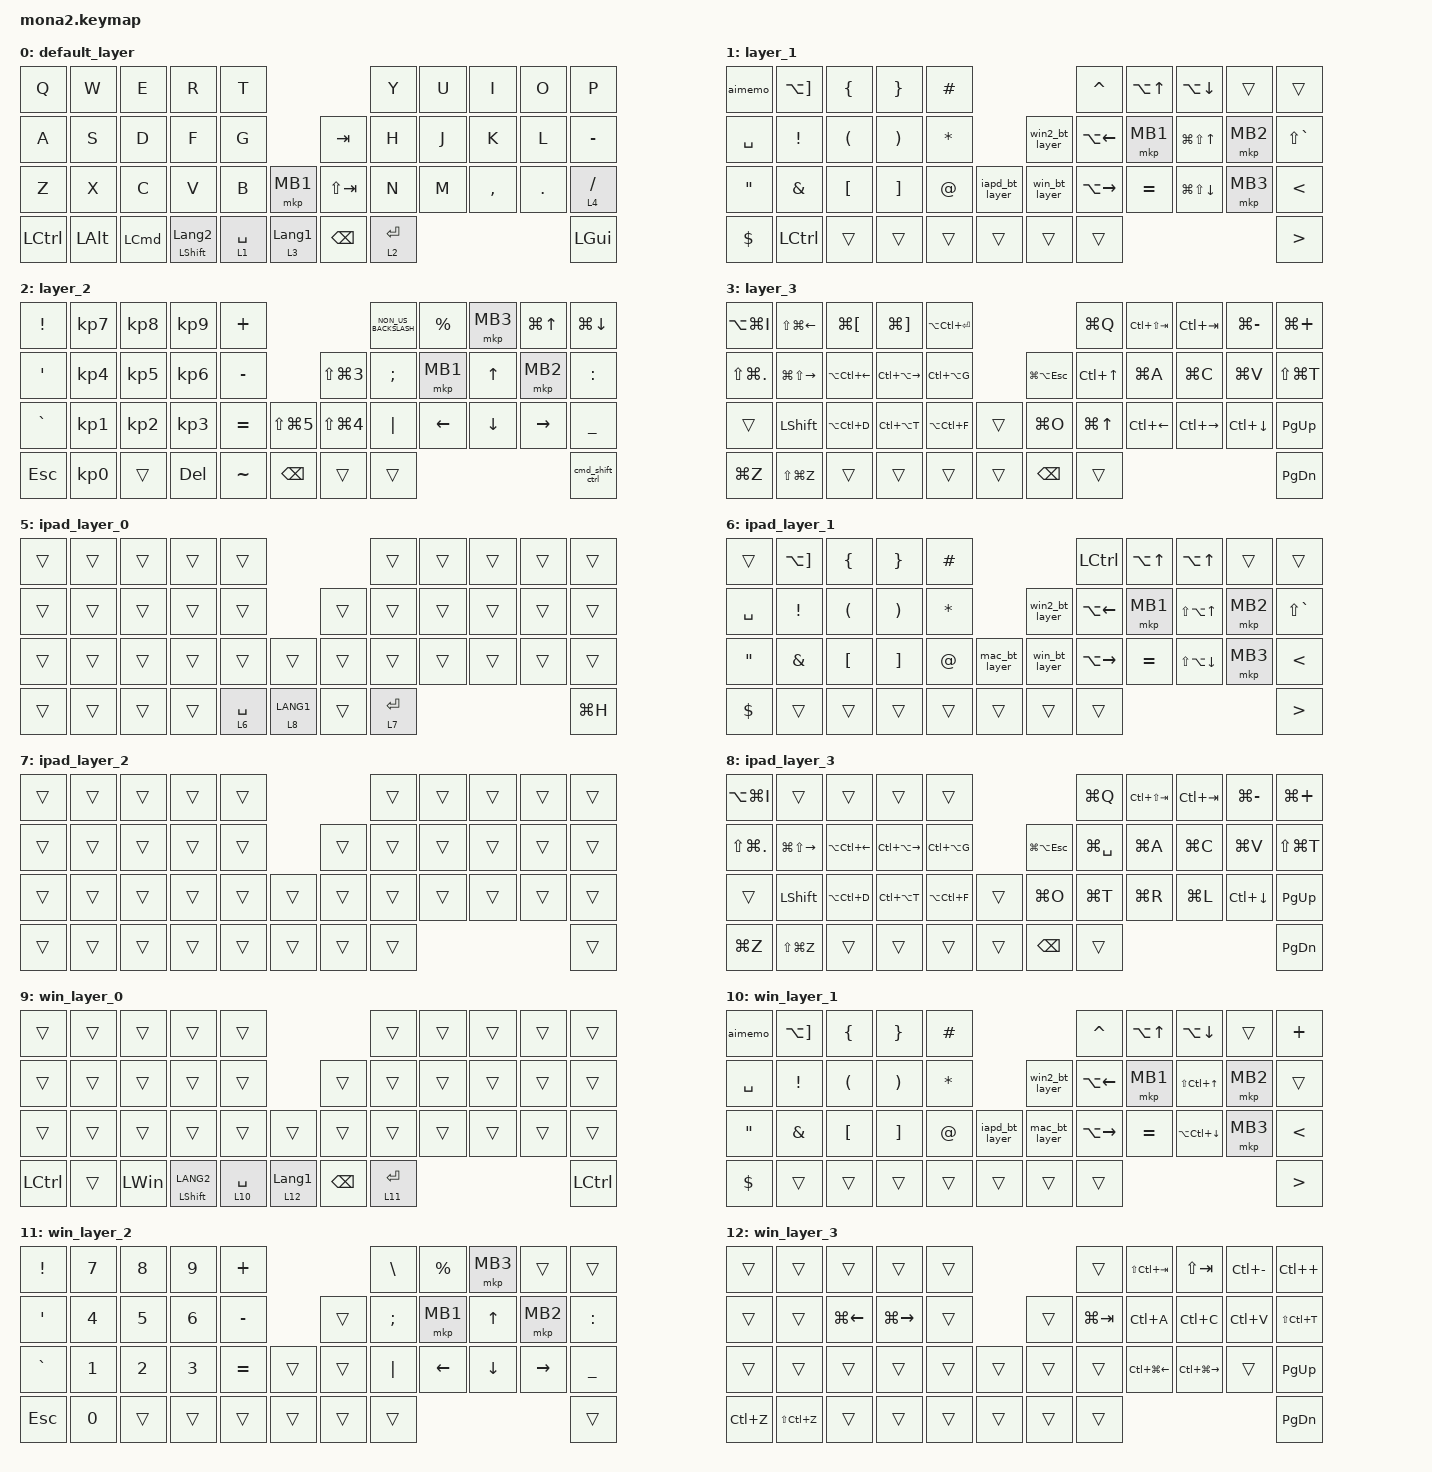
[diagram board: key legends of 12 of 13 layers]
#include <input/processors.dtsi>
#include <dt-bindings/zmk/input_transform.h>
#include <zephyr/dt-bindings/input/input-event-codes.h>
#include <behaviors.dtsi>
#include <dt-bindings/zmk/bt.h>
#include <dt-bindings/zmk/keys.h>
#include <dt-bindings/zmk/pointing.h>

#define ZMK_POINTING_DEFAULT_SCRL_VAL 100
#define MOUSE 5
#define SCROLL 6

&mt {
    flavor = "balanced";
    quick-tap-ms = <0>;
};

&lt {
    quick-tap-ms = <300>;
    flavor = "balanced";
};

/ {
    combos {
        compatible = "zmk,combos";

        layer4_ESC {
            bindings = <&lt 4 ESC>;
            key-positions = <39 38>;
        };

        tab {
            bindings = <&kp TAB>;
            key-positions = <11 12>;
        };

        cmd {
            bindings = <&none>;
            key-positions = <29 23 12>;
        };

        plus {
            bindings = <&none>;
            key-positions = <37 9>;
        };

        shift {
            bindings = <&none>;
            key-positions = <11 16 7 13 4>;
        };

        ctrl {
            bindings = <&none>;
            key-positions = <23 4 3 19>;
        };
    };

    macros {
        to_layer_0: to_layer_0 {
            compatible = "zmk,behavior-macro-one-param";
            #binding-cells = <1>;
            bindings = <&to 0 &macro_param_1to1 &kp MACRO_PLACEHOLDER>;
            label = "TO_LAYER_0";
        };

        mac_bt_layer: mac_bt_layer {
            compatible = "zmk,behavior-macro";
            #binding-cells = <0>;
            bindings = <&bt BT_SEL 0>, <&macro_wait_time 200>, <&to 0>;

            label = "MAC_BT_LAYER";
        };

        iapd_bt_layer: iapd_bt_layer {
            compatible = "zmk,behavior-macro";
            #binding-cells = <0>;
            bindings = <&bt BT_SEL 1>, <&macro_wait_time 200>, <&to 5>;

            label = "IAPD_BT_LAYER";
        };

        win_bt_layer: win_bt_layer {
            compatible = "zmk,behavior-macro";
            #binding-cells = <0>;
            bindings = <&bt BT_SEL 2>, <&macro_wait_time 200>, <&to 9>;

            label = "WIN_BT_LAYER";
        };

        win2_bt_layer: win2_bt_layer {
            compatible = "zmk,behavior-macro";
            #binding-cells = <0>;
            bindings = <&bt BT_SEL 3>, <&macro_wait_time 200>, <&to 9>;

            label = "WIN2_BT_LAYER";
        };

        aimemo: aimemo {
            compatible = "zmk,behavior-macro";
            #binding-cells = <0>;
            bindings =
                <&macro_press>,
                <&kp LEFT_SHIFT &kp LEFT_ALT &kp D>,
                <&macro_release>,
                <&kp LEFT_SHIFT &kp LEFT_ALT &kp D>;

            label = "AIMEMO";
        };

        cmd_shift_ctrl: cmd_shift_ctrl {
            compatible = "zmk,behavior-macro";
            #binding-cells = <0>;
            bindings = <&kp C &kp M &kp D &kp UNDERSCORE &kp S &kp H &kp I &kp F &kp T &kp UNDERSCORE &kp A &kp L &kp T &kp UNDERSCORE>;
            label = "CMD_SHIFT_CTRL";
        };

        cmd_shift_ctrl__: cmd_shift_ctrl__ {
            compatible = "zmk,behavior-macro";
            #binding-cells = <0>;
            bindings = <&kp LEFT_GUI &kp LEFT_SHIFT &kp LEFT_CONTROL>;
            label = "CMD_SHIFT_CTRL__";
        };

        loupedeck_open: loupedeck {
            compatible = "zmk,behavior-macro";
            #binding-cells = <0>;
            bindings = <&kp LS(LG(LA(L)))>;
            label = "LOUPEDECK";
        };

        Googlechroom_open: Googlechroom_open {
            compatible = "zmk,behavior-macro";
            #binding-cells = <0>;
            bindings = <&kp LS(LA(LG(C)))>, <&macro_press>;

            label = "GOOGLECHROOM_OPEN";
        };

        obsidian_open: obsidian_open {
            compatible = "zmk,behavior-macro";
            #binding-cells = <0>;
            bindings = <&kp LS(LA(LG(O)))>;
            label = "OBSIDIAN_OPEN";
        };

        cco_foruda_open: cco_foruda_open {
            compatible = "zmk,behavior-macro";
            #binding-cells = <0>;
            bindings = <&kp LS(LA(LG(H)))>;
            label = "CCO_FORUDA_OPEN";
        };

        new_d_folder: new_d_folder {
            compatible = "zmk,behavior-macro";
            #binding-cells = <0>;
            bindings = <&kp LS(LA(LG(Y)))>;
            label = "NEW_D_FOLDER";
        };

        zmk_git_url_open: zmk_git_url_open {
            compatible = "zmk,behavior-macro";
            #binding-cells = <0>;
            bindings = <&kp LS(LA(LG(A)))>;
            label = "ZMK_GIT_URL_OPEN";
        };

        System_keyboard_shortcut: System_keyboard_shortcut {
            compatible = "zmk,behavior-macro";
            #binding-cells = <0>;
            bindings = <&kp LS(LA(LG(B)))>;
            label = "SYSTEM_KEYBOARD_SHORTCUT";
        };

        System_Bluetooth_open: System_Bluetooth_open {
            compatible = "zmk,behavior-macro";
            #binding-cells = <0>;
            bindings = <&kp LS(LA(LG(E)))>;
            label = "SYSTEM_BLUETOOTH_OPEN";
        };

        vscode_open: vscode_open {
            compatible = "zmk,behavior-macro";
            #binding-cells = <0>;
            bindings = <&kp LS(LA(LG(F)))>;
            label = "VSCODE_OPEN";
        };

        slack_open: slack_open {
            compatible = "zmk,behavior-macro";
            #binding-cells = <0>;
            bindings = <&kp LS(LA(LG(G)))>;
            label = "SLACK_OPEN";
        };
    };

    behaviors {
        lt_to_layer_0: lt_to_layer_0 {
            compatible = "zmk,behavior-hold-tap";
            label = "LAYER_TAP_TO_0";
            bindings = <&mo>, <&to_layer_0>;

            #binding-cells = <2>;
            tapping-term-ms = <200>;
        };

        scroll_up_down: mouse_wheel_up_down {
            compatible = "zmk,behavior-sensor-rotate";
            #sensor-binding-cells = <0>;
            bindings = <&msc SCRL_DOWN>, <&msc SCRL_UP>;

            tap-ms = <20>;
        };

        scroll_right_left: mouse_wheel_right_left {
            compatible = "zmk,behavior-sensor-rotate";
            #sensor-binding-cells = <0>;
            bindings = <&msc SCRL_LEFT>, <&msc SCRL_RIGHT>;

            tap-ms = <20>;
        };
    };

    keymap {
        compatible = "zmk,keymap";

        default_layer {
            bindings = <
&kp Q      &kp W         &kp E             &kp R                      &kp T                                           &kp Y        &kp U  &kp I      &kp O    &kp P
&kp A      &kp S         &kp D             &kp F                      &kp G                            &kp TAB        &kp H        &kp J  &kp K      &kp L    &kp MINUS
&kp Z      &kp X         &kp C             &kp V                      &kp B        &mkp MB1            &kp LS(TAB)    &kp N        &kp M  &kp COMMA  &kp DOT  &lt 4 SLASH
&kp LCTRL  &kp LEFT_ALT  &kp LEFT_COMMAND  &mt LEFT_SHIFT LANGUAGE_2  &lt 1 SPACE  &lt 3 LANGUAGE_1    &kp BACKSPACE  &lt 2 ENTER                             &kp LEFT_GUI
            >;

            sensor-bindings = <&scroll_up_down>;
        };

        layer_1 {
            bindings = <
&aimemo            &kp LA(RIGHT_BRACKET)  &kp LEFT_BRACE        &kp RIGHT_BRACE        &kp HASH                                        &kp CARET           &kp LA(UP_ARROW)  &kp LA(DOWN)          &trans    &trans
&kp SPACE          &kp EXCLAMATION        &kp LEFT_PARENTHESIS  &kp RIGHT_PARENTHESIS  &kp ASTERISK                    &win2_bt_layer  &kp LA(LEFT_ARROW)  &mkp MB1          &kp LG(LS(UP_ARROW))  &mkp MB2  &kp LS(GRAVE)
&kp DOUBLE_QUOTES  &kp AMPERSAND          &kp LEFT_BRACKET      &kp RIGHT_BRACKET      &kp AT_SIGN   &iapd_bt_layer    &win_bt_layer   &kp LA(RIGHT)       &kp EQUAL         &kp LG(LS(DOWN))      &mkp MB3  &kp LESS_THAN
&kp DOLLAR         &kp LCTRL              &trans                &trans                 &trans        &trans            &trans          &trans                                                                &kp GREATER_THAN
            >;

            sensor-bindings = <&scroll_right_left>;
        };

        layer_2 {
            bindings = <
&kp EXCLAMATION  &kp KP_NUMBER_7  &kp KP_NUMBER_8  &kp KP_NUMBER_9  &kp PLUS                                                 &kp NON_US_BACKSLASH  &kp PERCENT     &mkp MB3        &kp LG(UP_ARROW)  &kp LG(DOWN)
&kp SQT          &kp KP_NUMBER_4  &kp KP_NUMBER_5  &kp KP_NUMBER_6  &kp MINUS                          &kp LS(LG(NUMBER_3))  &kp SEMICOLON         &mkp MB1        &kp UP_ARROW    &mkp MB2          &kp COLON
&kp GRAVE        &kp KP_NUMBER_1  &kp KP_NUMBER_2  &kp KP_NUMBER_3  &kp EQUAL  &kp LS(LG(NUMBER_5))    &kp LS(LG(NUMBER_4))  &kp PIPE              &kp LEFT_ARROW  &kp DOWN_ARROW  &kp RIGHT_ARROW   &kp UNDER
&kp ESC          &kp KP_NUMBER_0  &trans           &kp DELETE       &kp TILDE  &kp BACKSPACE           &trans                &trans                                                                  &cmd_shift_ctrl
            >;

            sensor-bindings = <&scroll_up_down>;
        };

        layer_3 {
            bindings = <
&kp LA(LG(I))       &kp LS(LG(LEFT))   &kp LG(LEFT_BRACKET)  &kp LG(RIGHT_BRACKET)  &kp LA(LC(ENTER))                             &kp LG(Q)         &kp LC(LS(TAB))     &kp LC(TAB)    &kp LG(MINUS)  &kp LG(PLUS)
&kp LS(LG(PERIOD))  &kp LG(LS(RIGHT))  &kp LA(LC(LEFT))      &kp LC(LA(RIGHT))      &kp LC(LA(G))                &kp LG(LA(ESC))  &kp LC(UP_ARROW)  &kp LG(A)           &kp LG(C)      &kp LG(V)      &kp LS(LG(T))
&trans              &kp LEFT_SHIFT     &kp LA(LC(D))         &kp LC(LA(T))          &kp LA(LC(F))      &trans    &kp LG(O)        &kp LG(UP_ARROW)  &kp LC(LEFT_ARROW)  &kp LC(RIGHT)  &kp LC(DOWN)   &kp PAGE_UP
&kp LG(Z)           &kp LS(LG(Z))      &trans                &trans                 &trans             &trans    &kp BACKSPACE    &trans                                                              &kp PAGE_DOWN
            >;

            sensor-bindings = <&inc_dec_kp C_VOL_DN C_VOL_UP>;
        };

        layer_4 {
            bindings = <
&kp F1                     &kp F2                  &kp F3             &kp F4         &kp F5                                           &bt BT_SEL 0     &bt BT_SEL 1        &bt BT_SEL 2    &bt BT_SEL 3   &bt BT_SEL 4
&zmk_git_url_open          &trans                  &kp LS(LG(LA(D)))  &kp LA(LG(L))  &cco_foruda_open                    &trans       &loupedeck_open  &Googlechroom_open  &obsidian_open  &slack_open    &vscode_open
&kp LS(LA(LG(U)))          &trans                  &new_d_folder      &trans         &trans            &trans            &bootloader  &trans           &trans              &trans          &kp LA(SPACE)  &trans
&System_keyboard_shortcut  &System_Bluetooth_open  &trans             &trans         &bt BT_CLR        &bt BT_CLR_ALL    &trans       &trans                                                              &trans
            >;

            sensor-bindings = <&inc_dec_kp C_VOLUME_UP C_VOL_DN>;
        };

        ipad_layer_0 {
            bindings = <
&trans  &trans  &trans  &trans  &trans                              &trans       &trans  &trans  &trans  &trans
&trans  &trans  &trans  &trans  &trans                      &trans  &trans       &trans  &trans  &trans  &trans
&trans  &trans  &trans  &trans  &trans       &trans         &trans  &trans       &trans  &trans  &trans  &trans
&trans  &trans  &trans  &trans  &lt 6 SPACE  &lt 8 LANG1    &trans  &lt 7 ENTER                          &kp LG(H)
            >;

            sensor-bindings = <&scroll_up_down>;
        };

        ipad_layer_1 {
            bindings = <
&trans             &kp LA(RIGHT_BRACKET)  &kp LEFT_BRACE        &kp RIGHT_BRACE        &kp HASH                                       &kp LCTRL            &kp LA(UP)  &kp LA(UP_ARROW)  &trans    &trans
&kp SPACE          &kp EXCLAMATION        &kp LEFT_PARENTHESIS  &kp RIGHT_PARENTHESIS  &kp ASTERISK                   &win2_bt_layer  &kp LA(LEFT)         &mkp MB1    &kp LS(LA(UP))    &mkp MB2  &kp LS(GRAVE)
&kp DOUBLE_QUOTES  &kp AMPERSAND          &kp LEFT_BRACKET      &kp RIGHT_BRACKET      &kp AT_SIGN   &mac_bt_layer    &win_bt_layer   &kp LA(RIGHT_ARROW)  &kp EQUAL   &kp LS(LA(DOWN))  &mkp MB3  &kp LESS_THAN
&kp DOLLAR         &trans                 &trans                &trans                 &trans        &trans           &trans          &trans                                                       &kp GREATER_THAN
            >;

            sensor-bindings = <&scroll_up_down>;
        };

        ipad_layer_2 {
            bindings = <
&trans  &trans  &trans  &trans  &trans                    &trans  &trans  &trans  &trans  &trans
&trans  &trans  &trans  &trans  &trans            &trans  &trans  &trans  &trans  &trans  &trans
&trans  &trans  &trans  &trans  &trans  &trans    &trans  &trans  &trans  &trans  &trans  &trans
&trans  &trans  &trans  &trans  &trans  &trans    &trans  &trans                          &trans
            >;
        };

        ipad_layer_3 {
            bindings = <
&kp LA(LG(I))       &trans             &trans            &trans             &trans                                    &kp LG(Q)      &kp LC(LS(TAB))  &kp LC(TAB)  &kp LG(MINUS)  &kp LG(PLUS)
&kp LS(LG(PERIOD))  &kp LG(LS(RIGHT))  &kp LA(LC(LEFT))  &kp LC(LA(RIGHT))  &kp LC(LA(G))            &kp LG(LA(ESC))  &kp LG(SPACE)  &kp LG(A)        &kp LG(C)    &kp LG(V)      &kp LS(LG(T))
&trans              &kp LEFT_SHIFT     &kp LA(LC(D))     &kp LC(LA(T))      &kp LA(LC(F))  &trans    &kp LG(O)        &kp LG(T)      &kp LG(R)        &kp LG(L)    &kp LC(DOWN)   &kp PAGE_UP
&kp LG(Z)           &kp LS(LG(Z))      &trans            &trans             &trans         &trans    &kp BACKSPACE    &trans                                                      &kp PAGE_DOWN
            >;

            sensor-bindings = <&inc_dec_kp C_VOL_DN C_VOL_UP>;
        };

        win_layer_0 {
            bindings = <
&trans     &trans  &trans        &trans                &trans                                            &trans        &trans  &trans  &trans  &trans
&trans     &trans  &trans        &trans                &trans                             &trans         &trans        &trans  &trans  &trans  &trans
&trans     &trans  &trans        &trans                &trans        &trans               &trans         &trans        &trans  &trans  &trans  &trans
&kp LCTRL  &trans  &kp LEFT_WIN  &mt LEFT_SHIFT LANG2  &lt 10 SPACE  &lt 12 LANGUAGE_1    &kp BACKSPACE  &lt 11 ENTER                          &kp LCTRL
            >;
        };

        win_layer_1 {
            bindings = <
&aimemo            &kp LA(RIGHT_BRACKET)  &kp LEFT_BRACE        &kp RIGHT_BRACE        &kp HASH                                        &kp CARET      &kp LA(UP_ARROW)  &kp LA(DOWN)          &trans    &kp PLUS
&kp SPACE          &kp EXCLAMATION        &kp LEFT_PARENTHESIS  &kp RIGHT_PARENTHESIS  &kp ASTERISK                    &win2_bt_layer  &kp LA(LEFT)   &mkp MB1          &kp LS(LC(UP_ARROW))  &mkp MB2  &trans
&kp DOUBLE_QUOTES  &kp AMPERSAND          &kp LEFT_BRACKET      &kp RIGHT_BRACKET      &kp AT_SIGN   &iapd_bt_layer    &mac_bt_layer   &kp LA(RIGHT)  &kp EQUAL         &kp LA(LC(DOWN))      &mkp MB3  &kp LESS_THAN
&kp DOLLAR         &trans                 &trans                &trans                 &trans        &trans            &trans          &trans                                                           &kp GREATER_THAN
            >;
        };

        win_layer_2 {
            bindings = <
&kp EXCLAMATION  &kp N7  &kp N8  &kp N9  &kp PLUS                     &kp BACKSLASH  &kp PERCENT  &mkp MB3      &trans     &trans
&kp SQT          &kp N4  &kp N5  &kp N6  &kp MINUS            &trans  &kp SEMICOLON  &mkp MB1     &kp UP_ARROW  &mkp MB2   &kp COLON
&kp GRAVE        &kp N1  &kp N2  &kp N3  &kp EQUAL  &trans    &trans  &kp PIPE       &kp LEFT     &kp DOWN      &kp RIGHT  &kp UNDERSCORE
&kp ESC          &kp N0  &trans  &trans  &trans     &trans    &trans  &trans                                               &trans
            >;
        };

        win_layer_3 {
            bindings = <
&trans     &trans         &trans        &trans         &trans                    &trans       &kp LS(LC(TAB))   &kp LS(TAB)        &kp LC(MINUS)  &kp LC(PLUS)
&trans     &trans         &kp LG(LEFT)  &kp LG(RIGHT)  &trans            &trans  &kp LG(TAB)  &kp LC(A)         &kp LC(C)          &kp LC(V)      &kp LS(LC(T))
&trans     &trans         &trans        &trans         &trans  &trans    &trans  &trans       &kp LC(LG(LEFT))  &kp LC(LG(RIGHT))  &trans         &kp PAGE_UP
&kp LC(Z)  &kp LS(LC(Z))  &trans        &trans         &trans  &trans    &trans  &trans                                                           &kp PAGE_DOWN
            >;
        };
    };
};
